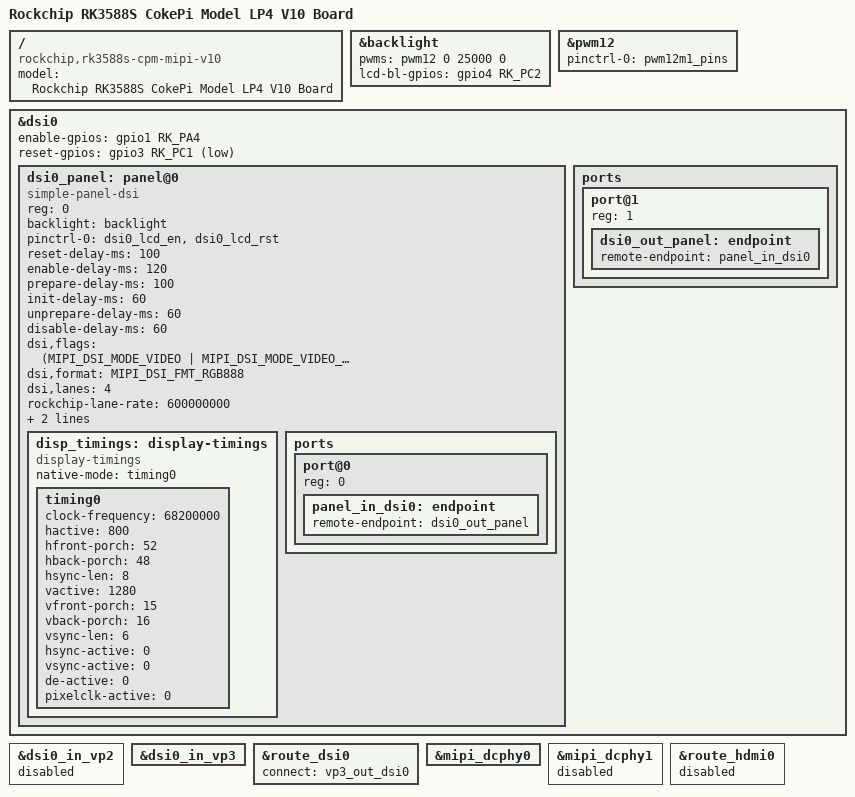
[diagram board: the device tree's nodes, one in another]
// SPDX-License-Identifier: (GPL-2.0+ OR MIT)
/*
 * Copyright (c) 2021 Rockchip Electronics Co., Ltd.
 *
 */

/dts-v1/;

#include "rk3588s-cokepi-lite.dtsi"
#include "rk3588-linux.dtsi"

/ {
	model = "Rockchip RK3588S CokePi Model LP4 V10 Board";
	compatible = "rockchip,rk3588s-cpm-mipi-v10", "rockchip,rk3588s", "rockchip,rk3588";
};

&backlight {
	pwms = <&pwm12 0 25000 0>;
	status = "okay";

	lcd-bl-gpios = <&gpio4 RK_PC2 GPIO_ACTIVE_HIGH>; /* Pseudo */
};

&pwm12 {
	status = "okay";
	pinctrl-names = "active";
	pinctrl-0 = <&pwm12m1_pins>;
};

/*
 * mipi_dcphy0 needs to be enabled
 * when dsi0 is enabled
 */
&dsi0 {
	status = "okay";
	//rockchip,lane-rate = <600>;
	enable-gpios = <&gpio1 RK_PA4 GPIO_ACTIVE_HIGH>;
	reset-gpios = <&gpio3 RK_PC1 GPIO_ACTIVE_LOW>;

	dsi0_panel: panel@0 {
		status = "okay";
		compatible = "simple-panel-dsi";
		reg = <0>;
		backlight = <&backlight>;
		pinctrl-names = "default";
		pinctrl-0 = <&dsi0_lcd_en &dsi0_lcd_rst>;
		reset-delay-ms = <100>;
		enable-delay-ms = <120>;
		prepare-delay-ms = <100>;
		init-delay-ms = <60>;
		unprepare-delay-ms = <60>;
		disable-delay-ms = <60>;
		dsi,flags = <(MIPI_DSI_MODE_VIDEO | MIPI_DSI_MODE_VIDEO_BURST |
			MIPI_DSI_MODE_LPM | MIPI_DSI_MODE_EOT_PACKET)>;
		dsi,format = <MIPI_DSI_FMT_RGB888>;
		dsi,lanes  = <4>;

		rockchip-lane-rate = <600000000>;
		panel-init-sequence = [ /* mipi-xmz080cs6 */
			39 00 04 FF 98 81 03
			15 00 02 01 00
			15 00 02 02 00
			15 00 02 03 53
			15 00 02 04 53
			15 00 02 05 13
			15 00 02 06 04
			15 00 02 07 02
			15 00 02 08 02
			15 00 02 09 00
			15 00 02 0a 00
			15 00 02 0b 00
			15 00 02 0c 00
			15 00 02 0d 00
			15 00 02 0e 00
			15 00 02 0f 00
			15 00 02 10 00
			15 00 02 11 00
			15 00 02 12 00
			15 00 02 13 00
			15 00 02 14 00
			15 00 02 15 00
			15 00 02 16 00
			15 00 02 17 00
			15 00 02 18 00
			15 00 02 19 00
			15 00 02 1a 00
			15 00 02 1b 00
			15 00 02 1c 00
			15 00 02 1d 00
			15 00 02 1e c0
			15 00 02 1f 80
			15 00 02 20 02
			15 00 02 21 09
			15 00 02 22 00
			15 00 02 23 00
			15 00 02 24 00
			15 00 02 25 00
			15 00 02 26 00
			15 00 02 27 00
			15 00 02 28 55
			15 00 02 29 03
			15 00 02 2a 00
			15 00 02 2b 00
			15 00 02 2c 00
			15 00 02 2d 00
			15 00 02 2e 00
			15 00 02 2f 00
			15 00 02 30 00
			15 00 02 31 00
			15 00 02 32 00
			15 00 02 33 00
			15 00 02 34 00
			15 00 02 35 00
			15 00 02 36 00
			15 00 02 37 00
			15 00 02 38 3C
			15 00 02 39 00
			15 00 02 3a 00
			15 00 02 3b 00
			15 00 02 3c 00
			15 00 02 3d 00
			15 00 02 3e 00
			15 00 02 3f 00
			15 00 02 40 00
			15 00 02 41 00
			15 00 02 42 00
			15 00 02 43 00
			15 00 02 44 00
			15 00 02 50 01
			15 00 02 51 23
			15 00 02 52 45
			15 00 02 53 67
			15 00 02 54 89
			15 00 02 55 ab
			15 00 02 56 01
			15 00 02 57 23
			15 00 02 58 45
			15 00 02 59 67
			15 00 02 5a 89
			15 00 02 5b ab
			15 00 02 5c cd
			15 00 02 5d ef
			15 00 02 5e 01
			15 00 02 5f 08
			15 00 02 60 02
			15 00 02 61 02
			15 00 02 62 0A
			15 00 02 63 15
			15 00 02 64 14
			15 00 02 65 02
			15 00 02 66 11
			15 00 02 67 10
			15 00 02 68 02
			15 00 02 69 0F
			15 00 02 6a 0E
			15 00 02 6b 02
			15 00 02 6c 0D
			15 00 02 6d 0C
			15 00 02 6e 06
			15 00 02 6f 02
			15 00 02 70 02
			15 00 02 71 02
			15 00 02 72 02
			15 00 02 73 02
			15 00 02 74 02
			15 00 02 75 06
			15 00 02 76 02
			15 00 02 77 02
			15 00 02 78 0A
			15 00 02 79 15
			15 00 02 7a 14
			15 00 02 7b 02
			15 00 02 7c 10
			15 00 02 7d 11
			15 00 02 7e 02
			15 00 02 7f 0C
			15 00 02 80 0D
			15 00 02 81 02
			15 00 02 82 0E
			15 00 02 83 0F
			15 00 02 84 08
			15 00 02 85 02
			15 00 02 86 02
			15 00 02 87 02
			15 00 02 88 02
			15 00 02 89 02
			15 00 02 8A 02
			39 00 04 FF 98 81 04
			15 00 02 6C 15
			15 00 02 6E 30
			15 00 02 6F 33
			15 00 02 8D 1F
			15 00 02 87 BA
			15 00 02 26 76
			15 00 02 B2 D1
			15 00 02 35 1F
			15 00 02 33 14
			15 00 02 3A A9
			15 00 02 3B 3D
			15 00 02 38 01
			15 00 02 39 00
			39 00 04 FF 98 81 01
			15 00 02 22 0A
			15 00 02 31 00
			15 00 02 40 53
			15 00 02 50 C0
			15 00 02 51 C0
			15 00 02 53 47
			15 00 02 55 46
			15 00 02 60 28
			15 00 02 2E C8
			15 00 02 A0 01
			15 00 02 A1 10
			15 00 02 A2 1B
			15 00 02 A3 0C
			15 00 02 A4 14
			15 00 02 A5 25
			15 00 02 A6 1A
			15 00 02 A7 1D
			15 00 02 A8 68
			15 00 02 A9 1B
			15 00 02 AA 26
			15 00 02 AB 5B
			15 00 02 AC 1B
			15 00 02 AD 17
			15 00 02 AE 4F
			15 00 02 AF 24
			15 00 02 B0 2A
			15 00 02 B1 4E
			15 00 02 B2 5F
			15 00 02 B3 39
			15 00 02 C0 0F
			15 00 02 C1 1B
			15 00 02 C2 27
			15 00 02 C3 16
			15 00 02 C4 14
			15 00 02 C5 28
			15 00 02 C6 1D
			15 00 02 C7 21
			15 00 02 C8 6C
			15 00 02 C9 1B
			15 00 02 CA 26
			15 00 02 CB 5B
			15 00 02 CC 1B
			15 00 02 CD 1B
			15 00 02 CE 4F
			15 00 02 CF 24
			15 00 02 D0 2A
			15 00 02 D1 4E
			15 00 02 D2 5F
			15 00 02 D3 39
			39 00 04 FF 98 81 00
			15 00 02 35 00
			05 78 01 11
			05 14 01 29
		];

		disp_timings: display-timings {
			compatible = "display-timings";
			native-mode = <&timing0>;
			timing0: timing0 { /* mipi-xmz080cs6 */
				clock-frequency = <68200000>;
				hactive = <800>;
				hfront-porch = <52>;
				hback-porch = <48>;
				hsync-len = <8>;
				vactive = <1280>;
				vfront-porch = <15>;
				vback-porch = <16>;
				vsync-len = <6>;
				hsync-active = <0>;
				vsync-active = <0>;
				de-active = <0>;
				pixelclk-active = <0>;
			};
		};

		ports {
			#address-cells = <1>;
			#size-cells = <0>;

			port@0 {
				reg = <0>;
				panel_in_dsi0: endpoint {
					remote-endpoint = <&dsi0_out_panel>;
				};
			};
		};
	};

	ports {
		#address-cells = <1>;
		#size-cells = <0>;

		port@1 {
			reg = <1>;
			dsi0_out_panel: endpoint {
				remote-endpoint = <&panel_in_dsi0>;
			};
		};
	};

};

&dsi0_in_vp2 {
	status = "disabled";
};

&dsi0_in_vp3 {
	status = "okay";
};

&route_dsi0 {
	status = "okay";
	//status = "disabled";
	connect = <&vp3_out_dsi0>;
};

&mipi_dcphy0 {
	status = "okay";
};

&mipi_dcphy1 {
	status = "disabled";
};

&route_hdmi0 {
	status = "disabled";
};
